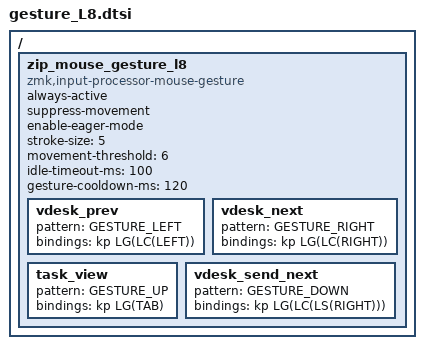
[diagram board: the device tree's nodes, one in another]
#include <dt-bindings/zmk/keys.h>
#include <dt-bindings/zmk/mouse-gesture.h>

/ {
    zip_mouse_gesture_l8: zip_mouse_gesture_l8 {
        compatible = "zmk,input-processor-mouse-gesture";
        #input-processor-cells = <0>;

        always-active;        // レイヤータップで遷移するため起動キー不要
        suppress-movement;    // このレイヤー中はカーソルを固定する
        enable-eager-mode;
        stroke-size = <5>;
        movement-threshold = <6>;
        idle-timeout-ms = <100>;
        gesture-cooldown-ms = <120>;

        // 仮想デスクトップ操作
        vdesk_prev       { pattern = <GESTURE_LEFT>;  bindings = <&kp LG(LC(LEFT))>;      };
        vdesk_next       { pattern = <GESTURE_RIGHT>; bindings = <&kp LG(LC(RIGHT))>;     };
        task_view        { pattern = <GESTURE_UP>;    bindings = <&kp LG(TAB)>;           };
        vdesk_send_next  { pattern = <GESTURE_DOWN>;  bindings = <&kp LG(LC(LS(RIGHT)))>; };
    };
};
